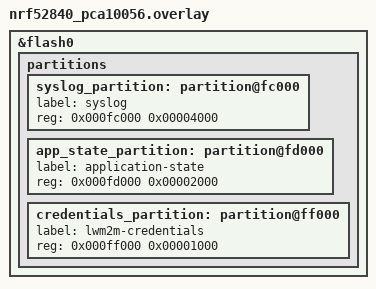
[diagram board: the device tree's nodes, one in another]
&flash0 {
	partitions {
		syslog_partition: partition@fc000 {
			label = "syslog";
			reg = <0x000fc000 0x00004000>;
		};

		app_state_partition: partition@fd000 {
			label = "application-state";
			reg = <0x000fd000 0x00002000>;
		};

		credentials_partition: partition@ff000 {
			label = "lwm2m-credentials";
			reg = <0x000ff000 0x00001000>;
		};
	};
};
